# RE01_1500KB register map
Vendor: Renesas Electronics Corporation; Series: RE01_1500KB; File version: 1.20
CPU: CM0PLUS r0p1, little endian, MPU, no FPU, VTOR, 2 interrupt priority bits
Registers are 8-bit, read-write, reset 0x0 unless marked. A register's access mark holds for its fields unless they carry their own. Offsets are from the block's base; [hi:lo] are bit positions; {n}, {i} and the like mark numbered series.

## CCC
Base 0x40080400
0x00 ADJUSTR 32-bit
  [8:0] ADJUST
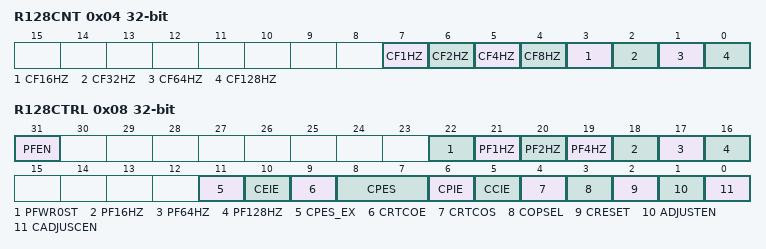
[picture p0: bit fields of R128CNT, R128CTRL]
0x04 R128CNT 32-bit ro
  [7] CF1HZ, [6] CF2HZ, [5] CF4HZ, [4] CF8HZ, [3] CF16HZ, [2] CF32HZ, [1] CF64HZ, [0] CF128HZ
0x08 R128CTRL 32-bit
  [31] PFEN
  [22] PFWR0ST ro
  [21] PF1HZ
  [20] PF2HZ
  [19] PF4HZ
  [18] PF16HZ
  [17] PF64HZ
  [16] PF128HZ
  [11] CPES_EX
  [10] CEIE
  [9] CRTCOE
  [8:7] CPES
    0=00; 1=01; 2=10; 3=11
  [6] CPIE
  [5] CCIE
  [4] CRTCOS
  [3] COPSEL
  [2] CRESET
  [1] ADJUSTEN
  [0] CADJUSCEN

## CRC — CRC Calculator
Base 0x40074000
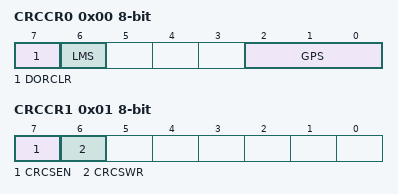
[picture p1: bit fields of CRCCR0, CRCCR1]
0x00 CRCCR0 — CRC Control Register0
  [7] DORCLR wo — CRCDOR Register Clear
    0=No effect; 1=Clears the CRCDOR/CRCDOR_HA/CRCDOR_BY register
  [6] LMS — CRC Calculation Switching
    0=Generates CRC for LSB first communication; 1=Generates CRC for MSB first communication
  [2:0] GPS — CRC Generating Polynomial Switching
    0=No calculation is executed; 1=8-bit CRC-8 (X8 + X2 + X + 1); 2=16-bit CRC-16 (X16 + X15 + X2 + 1); 3=16-bit CRC-CCITT (X16 + X12 + X5 + 1); 4=32-bit CRC-32(X32+X26+X23+X22+X16+X12+X11+X10+X8+X7+X5+X4+X2+X+1); 5=32-bit CRC-32C (X32+X28+X27+X26+X25+X23+X22+X20+X19+X18+X14+X13+X11+X10+X9+X8+X6+1); other=others (Setting prohibited)
0x01 CRCCR1 — CRC Control Register1
  [7] CRCSEN — Snoop enable bit
    0=Disabled; 1=Enabled
  [6] CRCSWR — Snoop-on-write/read switch bit
    0=Snoop-on-read; 1=Snoop-on-write
0x04 CRCDIR 32-bit — CRC Data Input Register
  [31:0] CRCDIR — Calculation input Data (Case of CRC-32, CRC-32C )
0x04 CRCDIR_BY (alternate view of CRCDIR) — CRC Data Input Register (byte access)
  [7:0] CRCDIR_BY — Calculation input Data ( Case of CRC-8, CRC-16 or CRC-CCITT )
0x08 CRCDOR 32-bit — CRC Data Output Register
  [31:0] CRCDOR — Calculation output Data (Case of CRC-32, CRC-32C )
0x08 CRCDOR_HA 16-bit (alternate view of CRCDOR) — CRC Data Output Register (halfword access)
  [15:0] CRCDOR_HA — Calculation output Data (Case of CRC-16 or CRC-CCITT )
0x08 CRCDOR_BY (alternate view of CRCDOR) — CRC Data Output Register(byte access)
  [7:0] CRCDOR_BY — Calculation output Data (Case of CRC-8 )
0x0C CRCSAR 16-bit — Snoop Address Register
  [13:0] CRCSA

## DBG — Debug Function
Base 0x4001B000
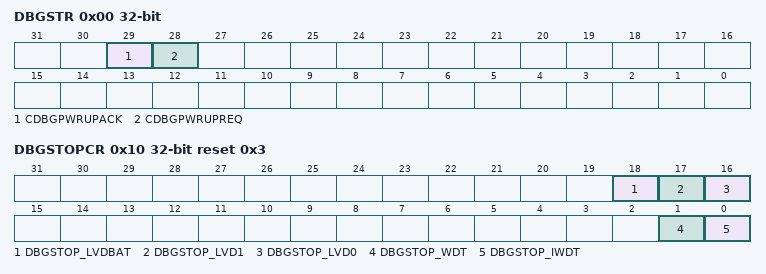
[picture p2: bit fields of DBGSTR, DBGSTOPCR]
0x00 DBGSTR 32-bit ro — Debug Status Register
  [29] CDBGPWRUPACK — Debug power-up acknowledge
    0=Debug power-up request is not acknowledged; 1=Debug power-up request is acknowledged
  [28] CDBGPWRUPREQ — Debug power-up request
    0=OCD is not requesting debug power-up; 1=OCD is requesting debug power-up
0x10 DBGSTOPCR 32-bit reset 0x3 — Debug Stop Control Register
  [18] DBGSTOP_LVDBAT — Mask bit for LVDBAT reset or interrupt
    0=Enable LVDBAT reset or interrupt; 1=Mask LVDBAT reset or interrupt
  [17] DBGSTOP_LVD1 — Mask bit for LVD1 reset or interrupt
    0=Enable LVD1 reset or interrupt; 1=Mask LVD1 reset or interrupt
  [16] DBGSTOP_LVD0 — Mask bit for LVD0 reset or interrupt
    0=Enable LVD0 reset or interrupt; 1=Mask LVD0 reset or interrupt
  [1] DBGSTOP_WDT — Mask bit for WDT reset/interrupt
    0=Enable WDT reset; 1=Mask WDT reset/interrupt
  [0] DBGSTOP_IWDT — Mask bit for IWDT reset/interrupt
    0=Enable IWDT reset; 1=Mask IWDT reset/interrupt

## DIL
Base 0x40084500
{0x0+4i} IDR{i} 32-bit (i=0..3)
{0x10+4i} ODR{i} 32-bit ro reset 0xFFFFFFFF (i=0..3)

## DIV
Base 0x40084600; alternate view of LPG
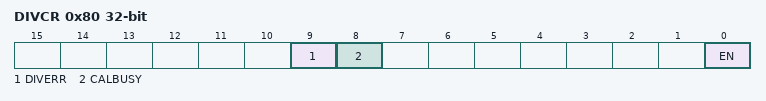
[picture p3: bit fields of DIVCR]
0x80 DIVCR 32-bit
  [9] DIVERR ro, [8] CALBUSY ro, [0] EN wo
0x84 DIVIDEND 32-bit
0x88 DIVSOR 32-bit
0x8C QUOTIENT 32-bit
0x90 REMAINDER 32-bit

## DMA — Direct Memory Access Controller Interface 0
Base 0x40005200
0x00 DMAST — DMAC Module Activation Register
  [0] DMST — DMAC Operation Enable
    0=Disabled; 1=Enabled
